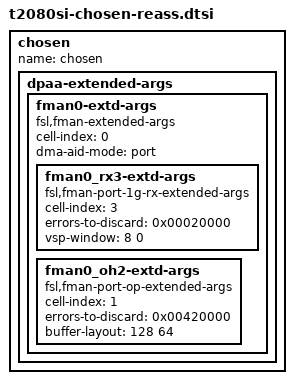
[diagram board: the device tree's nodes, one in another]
chosen {
	name = "chosen";

	dpaa-extended-args {
		fman0-extd-args {
			cell-index = <0>;
			compatible = "fsl,fman-extended-args";
			dma-aid-mode = "port";
			fman0_rx3-extd-args {
				cell-index = <3>;
				compatible = "fsl,fman-port-1g-rx-extended-args";
				errors-to-discard = <0x00020000>;
				/* Define Virtual storage profile */
				/* <number of profiles, default profile id> */
				vsp-window = <8 0>;
			};
			fman0_oh2-extd-args {
				cell-index = <1>;
				compatible = "fsl,fman-port-op-extended-args";
				errors-to-discard = <0x00420000>;
				/* Define buffer layout parameters. Can be used
				 * in fragmentation or header manip operations
				 */
				/* <manip extra space, data alignment> */
				buffer-layout = <128 64>;
			};
		};
	};
};
